# DSS_EDP0_V2A_S_CORE_VP_REGS_SAPB register map
Vendor: Texas Instruments
Peripheral module from a debugger description file (folder J7ES).
Registers are 32-bit, read-only, reset values left out (the file's numbers can be read two ways) unless marked. A register's access mark holds for its fields unless they carry their own. Offsets are as the file gives them; lines under a group give offsets from that group; [hi:lo] are bit positions; {n}, {i} and the like mark numbered series; 'fields as' and 'values as' point back to an identical list; <NAME> marks a mode.

## DSS_EDP0_V2A_S_CORE_VP_REGS_SAPB
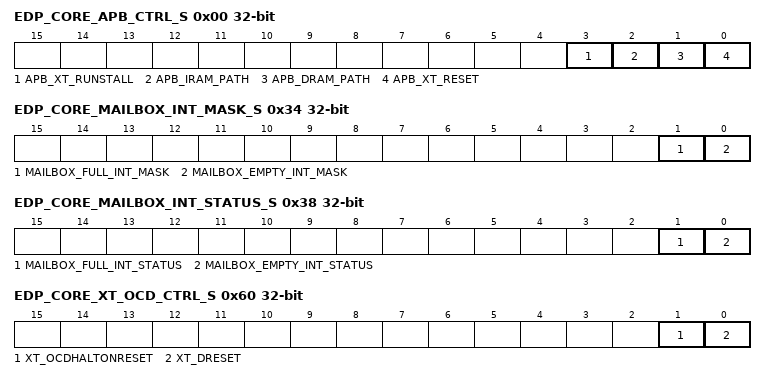
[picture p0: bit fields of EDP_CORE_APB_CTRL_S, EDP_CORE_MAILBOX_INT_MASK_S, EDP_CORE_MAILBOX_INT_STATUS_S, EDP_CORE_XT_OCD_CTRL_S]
0x00 EDP_CORE_APB_CTRL_S access per field — APB control register (SAPB)
  [3] APB_XT_RUNSTALL rw — Not used
  [2] APB_IRAM_PATH rw — Not used
  [1] APB_DRAM_PATH rw — Not used
  [0] APB_XT_RESET rw — Not used
0x04 EDP_CORE_XT_INT_CTRL_S access per field — Internal CPU Interrupt Polarity Control Register.
  [1:0] XT_INT_POLARITY rw — Not used
0x08 EDP_CORE_MAILBOX_FULL_ADDR_S — Mailbox full indication status register. This register provides a status of the mailbox that is used to send messages from the Host processor to internal uCPU. Mailbox full flag can be a source of mailbox interrupt.
  [0] MAILBOX_FULL — Mailbox full indication.
0x0C EDP_CORE_MAILBOX_EMPTY_ADDR_S — Mailbox empty indication status register. This register provides a status of the mailbox that is used to send responses from the internal uCPU to host processor as a result of previously sent message. Mailbox empty flag can be a source of not-empty mailbox interrupt.
  [0] MAILBOX_EMPTY — Mailbox Empty indication
0x10 EDP_CORE_MAILBOX0_WR_DATA_S access per field — Mailbox write data register
  [7:0] MAILBOX0_WR_DATA rw — Mailbox write Data.
0x14 EDP_CORE_MAILBOX0_RD_DATA_S — Mailbox Read data register
  [7:0] MAILBOX0_RD_DATA — Mailbox Read data
0x18 EDP_CORE_KEEP_ALIVE_S — Software keep alive counter
  [7:0] KEEP_ALIVE_CNT — Software keep alive counter.
0x1C EDP_CORE_VER_l_S — Software Version Register.
  [7:0] VER_LSB — Software Version lower byte.
0x20 EDP_CORE_VER_H_S — Software Version Register.
  [7:0] VER_MSB — Software Version higher byte.
0x24 EDP_CORE_VER_LIB_L_ADDR_S — Software Library Version Register.
  [7:0] SW_LIB_VER_L — Software Library Version lower byte.
0x28 EDP_CORE_VER_LIB_H_ADDR_S — Software Library Version Register.
  [7:0] SW_LIB_VER_H — Software Library Version higher byte.
0x2C EDP_CORE_SW_DEBUG_l_S — Software/Firmware Debug Register.
  [7:0] SW_DEBUG_7_0 — Register used for debug purposes [lower byte].
0x30 EDP_CORE_SW_DEBUG_H_S — Software/Firmware Debug Register.
  [7:0] SW_DEBUG_15_8 — Register used for debug purposes [higher byte].
0x34 EDP_CORE_MAILBOX_INT_MASK_S access per field — Mailbox Interrupt mask register
  [1] MAILBOX_FULL_INT_MASK rw — Mailbox Full Interrupt mask
  [0] MAILBOX_EMPTY_INT_MASK rw — Mailbox Not-empty Interrupt mask
0x38 EDP_CORE_MAILBOX_INT_STATUS_S — Mailbox Interrupt Status register
  [1] MAILBOX_FULL_INT_STATUS — Mailbox full interrupt.
  [0] MAILBOX_EMPTY_INT_STATUS — Mailbox not-empty interrupt.
0x3C EDP_CORE_SW_CLK_l_S access per field — Core Clock frequency
  [7:0] SW_CLOCK_VAL_L rw — Not used.
0x40 EDP_CORE_SW_CLK_H_S access per field — Core Clock frequency
  [7:0] SW_CLOCK_VAL_H rw — Not used.
{0x44+4i} EDP_CORE_SW_EVENTS{i}_S (i=0..3) — Not used. 0x0 when read.
  [7:0] SW_EVENTS{8i+7}_{8i} — Not used.
0x60 EDP_CORE_XT_OCD_CTRL_S access per field — Internal CPU - On Chip Debug (OCD) Ctrl Register
  [1] XT_OCDHALTONRESET rw — Not used
  [0] XT_DRESET rw — Not used
0x64 EDP_CORE_XT_OCD_CTRL_RO_S — Internal CPU - OCD R0 mode configuration
  [0] XT_XOCDMODE — Internal CPU - OCD mode configuration
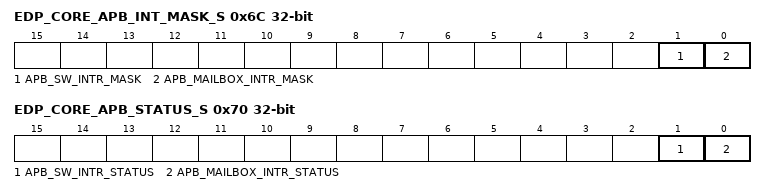
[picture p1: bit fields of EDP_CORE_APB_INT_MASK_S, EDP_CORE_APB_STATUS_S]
0x6C EDP_CORE_APB_INT_MASK_S access per field — APB Interrupt Mask Register
  [1] APB_SW_INTR_MASK rw — Not used.
  [0] APB_MAILBOX_INTR_MASK rw — Mailbox Interrupt mask
0x70 EDP_CORE_APB_STATUS_S — APB interrupt status register
  [1] APB_SW_INTR_STATUS — Not used.
  [0] APB_MAILBOX_INTR_STATUS — Mailbox Interrupt status.
